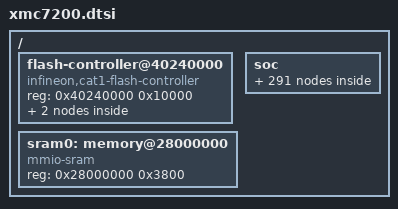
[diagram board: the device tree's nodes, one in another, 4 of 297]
/*
 * Copyright (c) 2023 Cypress Semiconductor Corporation (an Infineon company) or
 * an affiliate of Cypress Semiconductor Corporation
 *
 * SPDX-License-Identifier: Apache-2.0
 */

#include <mem.h>

/ {
	flash-controller@40240000 {
		compatible = "infineon,cat1-flash-controller";
		reg = <0x40240000 0x10000>;
		#address-cells = <1>;
		#size-cells = <1>;

		flash0: flash@10000000 {
			compatible = "soc-nv-flash";
			reg = <0x10000000 0x80000>;
			write-block-size = <512>;
			erase-block-size = <512>;
		};

		flash1: flash@10080000 {
			compatible = "soc-nv-flash";
			reg = <0x10080000 0x200000>;
			write-block-size = <512>;
			erase-block-size = <512>;
		};
	};

	/* 0x0000000028000800  _base_SRAM_CM0P =
	 * ((sram_base_address + sram_start_reserve) + sram_private_for_srom)
	 * TODO: Where better to keep srom private
	 */
	sram0: memory@28000000 {
		compatible = "mmio-sram";
		reg = <0x28000000 0x3800>;
	};

	soc {
		pinctrl: pinctrl@40300000 {
			compatible = "infineon,cat1-pinctrl";
			reg = <0x40300000 0x20000>;
		};

		hsiom: hsiom@40300000 {
			compatible = "infineon,cat1-hsiom";
			reg = <0x40300000 0x4000>;
			system-interrupts = <21 6>, <20 6>;
			status = "disabled";
		};

		gpio_prt0: gpio@40310000 {
			compatible = "infineon,cat1-gpio";
			reg = <0x40310000 0x80>;
			system-interrupts = <22 2>;
			gpio-controller;
			ngpios = <4>;
			status = "disabled";
			#gpio-cells = <2>;
		};

		gpio_prt1: gpio@40310080 {
			compatible = "infineon,cat1-gpio";
			reg = <0x40310080 0x80>;
			system-interrupts = <23 2>;
			gpio-controller;
			ngpios = <7>;
			status = "disabled";
			#gpio-cells = <2>;
		};

		gpio_prt2: gpio@40310100 {
			compatible = "infineon,cat1-gpio";
			reg = <0x40310100 0x80>;
			system-interrupts = <24 2>;
			gpio-controller;
			ngpios = <8>;
			status = "disabled";
			#gpio-cells = <2>;
		};

		gpio_prt3: gpio@40310180 {
			compatible = "infineon,cat1-gpio";
			reg = <0x40310180 0x80>;
			system-interrupts = <25 2>;
			gpio-controller;
			ngpios = <8>;
			status = "disabled";
			#gpio-cells = <2>;
		};

		gpio_prt4: gpio@40310200 {
			compatible = "infineon,cat1-gpio";
			reg = <0x40310200 0x80>;
			system-interrupts = <26 2>;
			gpio-controller;
			ngpios = <7>;
			status = "disabled";
			#gpio-cells = <2>;
		};

		gpio_prt5: gpio@40310280 {
			compatible = "infineon,cat1-gpio";
			reg = <0x40310280 0x80>;
			system-interrupts = <27 2>;
			gpio-controller;
			ngpios = <6>;
			status = "disabled";
			#gpio-cells = <2>;
		};

		gpio_prt6: gpio@40310300 {
			compatible = "infineon,cat1-gpio";
			reg = <0x40310300 0x80>;
			system-interrupts = <28 2>;
			gpio-controller;
			ngpios = <8>;
			status = "disabled";
			#gpio-cells = <2>;
		};

		gpio_prt7: gpio@40310380 {
			compatible = "infineon,cat1-gpio";
			reg = <0x40310380 0x80>;
			system-interrupts = <29 2>;
			gpio-controller;
			ngpios = <8>;
			status = "disabled";
			#gpio-cells = <2>;
		};

		gpio_prt8: gpio@40310400 {
			compatible = "infineon,cat1-gpio";
			reg = <0x40310400 0x80>;
			system-interrupts = <30 2>;
			gpio-controller;
			ngpios = <5>;
			status = "disabled";
			#gpio-cells = <2>;
		};

		gpio_prt9: gpio@40310480 {
			compatible = "infineon,cat1-gpio";
			reg = <0x40310480 0x80>;
			system-interrupts = <31 2>;
			gpio-controller;
			ngpios = <4>;
			status = "disabled";
			#gpio-cells = <2>;
		};

		gpio_prt10: gpio@40310500 {
			compatible = "infineon,cat1-gpio";
			reg = <0x40310500 0x80>;
			system-interrupts = <32 2>;
			gpio-controller;
			ngpios = <8>;
			status = "disabled";
			#gpio-cells = <2>;
		};

		gpio_prt11: gpio@40310580 {
			compatible = "infineon,cat1-gpio";
			reg = <0x40310580 0x80>;
			system-interrupts = <33 2>;
			gpio-controller;
			ngpios = <3>;
			status = "disabled";
			#gpio-cells = <2>;
		};

		gpio_prt12: gpio@40310600 {
			compatible = "infineon,cat1-gpio";
			reg = <0x40310600 0x80>;
			system-interrupts = <34 2>;
			gpio-controller;
			ngpios = <8>;
			status = "disabled";
			#gpio-cells = <2>;
		};

		gpio_prt13: gpio@40310680 {
			compatible = "infineon,cat1-gpio";
			reg = <0x40310680 0x80>;
			system-interrupts = <35 2>;
			gpio-controller;
			ngpios = <8>;
			status = "disabled";
			#gpio-cells = <2>;
		};

		gpio_prt14: gpio@40310700 {
			compatible = "infineon,cat1-gpio";
			reg = <0x40310700 0x80>;
			system-interrupts = <36 2>;
			gpio-controller;
			ngpios = <8>;
			status = "disabled";
			#gpio-cells = <2>;
		};

		gpio_prt15: gpio@40310780 {
			compatible = "infineon,cat1-gpio";
			reg = <0x40310780 0x80>;
			system-interrupts = <37 2>;
			gpio-controller;
			ngpios = <4>;
			status = "disabled";
			#gpio-cells = <2>;
		};

		gpio_prt16: gpio@40310800 {
			compatible = "infineon,cat1-gpio";
			reg = <0x40310800 0x80>;
			system-interrupts = <38 2>;
			gpio-controller;
			ngpios = <8>;
			status = "disabled";
			#gpio-cells = <2>;
		};

		gpio_prt17: gpio@40310880 {
			compatible = "infineon,cat1-gpio";
			reg = <0x40310880 0x80>;
			system-interrupts = <39 2>;
			gpio-controller;
			ngpios = <8>;
			status = "disabled";
			#gpio-cells = <2>;
		};

		gpio_prt18: gpio@40310900 {
			compatible = "infineon,cat1-gpio";
			reg = <0x40310900 0x80>;
			system-interrupts = <40 2>;
			gpio-controller;
			ngpios = <8>;
			status = "disabled";
			#gpio-cells = <2>;
		};

		gpio_prt19: gpio@40310980 {
			compatible = "infineon,cat1-gpio";
			reg = <0x40310980 0x80>;
			system-interrupts = <41 2>;
			gpio-controller;
			ngpios = <5>;
			status = "disabled";
			#gpio-cells = <2>;
		};

		gpio_prt20: gpio@40310a00 {
			compatible = "infineon,cat1-gpio";
			reg = <0x40310a00 0x80>;
			system-interrupts = <42 2>;
			gpio-controller;
			ngpios = <8>;
			status = "disabled";
			#gpio-cells = <2>;
		};

		gpio_prt21: gpio@40310a80 {
			compatible = "infineon,cat1-gpio";
			reg = <0x40310a80 0x80>;
			system-interrupts = <43 2>;
			gpio-controller;
			ngpios = <8>;
			status = "disabled";
			#gpio-cells = <2>;
		};

		gpio_prt22: gpio@40310b00 {
			compatible = "infineon,cat1-gpio";
			reg = <0x40310b00 0x80>;
			system-interrupts = <44 2>;
			gpio-controller;
			ngpios = <8>;
			status = "disabled";
			#gpio-cells = <2>;
		};

		gpio_prt23: gpio@40310b80 {
			compatible = "infineon,cat1-gpio";
			reg = <0x40310b80 0x80>;
			system-interrupts = <45 2>;
			gpio-controller;
			ngpios = <8>;
			status = "disabled";
			#gpio-cells = <2>;
		};

		gpio_prt24: gpio@40310c00 {
			compatible = "infineon,cat1-gpio";
			reg = <0x40310c00 0x80>;
			system-interrupts = <52 2>;
			gpio-controller;
			ngpios = <5>;
			status = "disabled";
			#gpio-cells = <2>;
		};

		gpio_prt25: gpio@40310c80 {
			compatible = "infineon,cat1-gpio";
			reg = <0x40310c80 0x80>;
			system-interrupts = <53 2>;
			gpio-controller;
			ngpios = <8>;
			status = "disabled";
			#gpio-cells = <2>;
		};

		gpio_prt26: gpio@40310d00 {
			compatible = "infineon,cat1-gpio";
			reg = <0x40310d00 0x80>;
			system-interrupts = <54 2>;
			gpio-controller;
			ngpios = <8>;
			status = "disabled";
			#gpio-cells = <2>;
		};

		gpio_prt27: gpio@40310d80 {
			compatible = "infineon,cat1-gpio";
			reg = <0x40310d80 0x80>;
			system-interrupts = <55 2>;
			gpio-controller;
			ngpios = <8>;
			status = "disabled";
			#gpio-cells = <2>;
		};

		gpio_prt28: gpio@40310e00 {
			compatible = "infineon,cat1-gpio";
			reg = <0x40310e00 0x80>;
			system-interrupts = <46 2>;
			gpio-controller;
			ngpios = <8>;
			status = "disabled";
			#gpio-cells = <2>;
		};

		gpio_prt29: gpio@40310e80 {
			compatible = "infineon,cat1-gpio";
			reg = <0x40310e80 0x80>;
			system-interrupts = <47 2>;
			gpio-controller;
			ngpios = <8>;
			status = "disabled";
			#gpio-cells = <2>;
		};

		gpio_prt30: gpio@40310f00 {
			compatible = "infineon,cat1-gpio";
			reg = <0x40310f00 0x80>;
			system-interrupts = <48 2>;
			gpio-controller;
			ngpios = <4>;
			status = "disabled";
			#gpio-cells = <2>;
		};

		gpio_prt31: gpio@40310f80 {
			compatible = "infineon,cat1-gpio";
			reg = <0x40310f80 0x80>;
			system-interrupts = <49 2>;
			gpio-controller;
			ngpios = <3>;
			status = "disabled";
			#gpio-cells = <2>;
		};

		gpio_prt32: gpio@40311000 {
			compatible = "infineon,cat1-gpio";
			reg = <0x40311000 0x80>;
			system-interrupts = <50 2>;
			gpio-controller;
			ngpios = <8>;
			status = "disabled";
			#gpio-cells = <2>;
		};

		gpio_prt33: gpio@40311080 {
			compatible = "infineon,cat1-gpio";
			reg = <0x40311080 0x80>;
			system-interrupts = <56 2>;
			gpio-controller;
			ngpios = <8>;
			status = "disabled";
			#gpio-cells = <2>;
		};

		gpio_prt34: gpio@40311100 {
			compatible = "infineon,cat1-gpio";
			reg = <0x40311100 0x80>;
			system-interrupts = <57 2>;
			gpio-controller;
			ngpios = <8>;
			status = "disabled";
			#gpio-cells = <2>;
		};

		scb0: scb@40600000 {
			compatible = "infineon,cat1-scb";
			reg = <0x40600000 0xfd0>;
			system-interrupts = <18 6>;
			status = "disabled";
		};

		scb1: scb@40610000 {
			compatible = "infineon,cat1-scb";
			reg = <0x40610000 0xfd0>;
			system-interrupts = <113 6>;
			status = "disabled";
		};

		scb2: scb@40620000 {
			compatible = "infineon,cat1-scb";
			reg = <0x40620000 0xfd0>;
			system-interrupts = <114 6>;
			status = "disabled";
		};

		scb3: scb@40630000 {
			compatible = "infineon,cat1-scb";
			reg = <0x40630000 0xfd0>;
			system-interrupts = <115 6>;
			status = "disabled";
		};

		scb4: scb@40640000 {
			compatible = "infineon,cat1-scb";
			reg = <0x40640000 0xfd0>;
			system-interrupts = <116 6>;
			status = "disabled";
		};

		scb5: scb@40650000 {
			compatible = "infineon,cat1-scb";
			reg = <0x40650000 0xfd0>;
			system-interrupts = <117 6>;
			status = "disabled";
		};

		scb6: scb@40660000 {
			compatible = "infineon,cat1-scb";
			reg = <0x40660000 0xfd0>;
			system-interrupts = <118 6>;
			status = "disabled";
		};

		scb7: scb@40670000 {
			compatible = "infineon,cat1-scb";
			reg = <0x40670000 0xfd0>;
			system-interrupts = <119 6>;
			status = "disabled";
		};

		scb8: scb@40680000 {
			compatible = "infineon,cat1-scb";
			reg = <0x40680000 0xfd0>;
			system-interrupts = <120 6>;
			status = "disabled";
		};

		scb9: scb@40690000 {
			compatible = "infineon,cat1-scb";
			reg = <0x40690000 0xfd0>;
			system-interrupts = <121 6>;
			status = "disabled";
		};

		scb10: scb@406a0000 {
			compatible = "infineon,cat1-scb";
			reg = <0x406a0000 0xfd0>;
			system-interrupts = <122 6>;
			status = "disabled";
		};

		watchdog0: watchdog@4026c000 {
			compatible = "infineon,cat1-watchdog";
			reg = <0x4026c000 0x80>;
			system-interrupts = <16 6>;
			status = "disabled";
		};

		mcwdt0: mcwdt@40268000 {
			compatible = "infineon,cat1-lp-timer";
			reg = <0x40268000 0x100>;
			system-interrupts = <13 6>;
			status = "disabled";
		};

		mcwdt1: mcwdt@40268100 {
			compatible = "infineon,cat1-lp-timer";
			reg = <0x40268100 0x100>;
			system-interrupts = <14 6>;
			status = "disabled";
		};

		mcwdt2: mcwdt@40268200 {
			compatible = "infineon,cat1-lp-timer";
			reg = <0x40268200 0x100>;
			system-interrupts = <15 6>;
			status = "disabled";
		};

		counter0_0_0: counter@40380000 {
			compatible = "infineon,cat1-counter";
			reg = <0x40380000 0x80>;
			system-interrupts = <519 6>;
			resolution = <16>;
			status = "disabled";
		};

		counter0_0_1: counter@40380080 {
			compatible = "infineon,cat1-counter";
			reg = <0x40380080 0x80>;
			system-interrupts = <520 6>;
			resolution = <16>;
			status = "disabled";
		};

		counter0_0_2: counter@40380100 {
			compatible = "infineon,cat1-counter";
			reg = <0x40380100 0x80>;
			system-interrupts = <521 6>;
			resolution = <16>;
			status = "disabled";
		};

		counter0_1_0: counter@40388000 {
			compatible = "infineon,cat1-counter";
			reg = <0x40388000 0x80>;
			system-interrupts = <534 6>;
			resolution = <16>;
			status = "disabled";
		};

		counter0_1_1: counter@40388080 {
			compatible = "infineon,cat1-counter";
			reg = <0x40388080 0x80>;
			system-interrupts = <535 6>;
			resolution = <16>;
			status = "disabled";
		};

		counter0_1_2: counter@40388100 {
			compatible = "infineon,cat1-counter";
			reg = <0x40388100 0x80>;
			system-interrupts = <536 6>;
			resolution = <16>;
			status = "disabled";
		};

		counter0_2_0: counter@40390000 {
			compatible = "infineon,cat1-counter";
			reg = <0x40390000 0x80>;
			system-interrupts = <550 6>;
			resolution = <32>;
			status = "disabled";
		};

		counter0_2_1: counter@40390080 {
			compatible = "infineon,cat1-counter";
			reg = <0x40390080 0x80>;
			system-interrupts = <551 6>;
			resolution = <32>;
			status = "disabled";
		};

		counter0_2_2: counter@40390100 {
			compatible = "infineon,cat1-counter";
			reg = <0x40390100 0x80>;
			system-interrupts = <552 6>;
			resolution = <32>;
			status = "disabled";
		};

		counter1_0_0: counter@40580000 {
			compatible = "infineon,cat1-counter";
			reg = <0x40580000 0x80>;
			system-interrupts = <435 6>;
			resolution = <16>;
			status = "disabled";
		};

		counter1_0_1: counter@40580080 {
			compatible = "infineon,cat1-counter";
			reg = <0x40580080 0x80>;
			system-interrupts = <436 6>;
			resolution = <16>;
			status = "disabled";
		};

		counter1_0_2: counter@40580100 {
			compatible = "infineon,cat1-counter";
			reg = <0x40580100 0x80>;
			system-interrupts = <437 6>;
			resolution = <16>;
			status = "disabled";
		};

		counter1_0_3: counter@40580180 {
			compatible = "infineon,cat1-counter";
			reg = <0x40580180 0x80>;
			system-interrupts = <438 6>;
			resolution = <16>;
			status = "disabled";
		};

		counter1_0_4: counter@40580200 {
			compatible = "infineon,cat1-counter";
			reg = <0x40580200 0x80>;
			system-interrupts = <439 6>;
			resolution = <16>;
			status = "disabled";
		};

		counter1_0_5: counter@40580280 {
			compatible = "infineon,cat1-counter";
			reg = <0x40580280 0x80>;
			system-interrupts = <440 6>;
			resolution = <16>;
			status = "disabled";
		};

		counter1_0_6: counter@40580300 {
			compatible = "infineon,cat1-counter";
			reg = <0x40580300 0x80>;
			system-interrupts = <441 6>;
			resolution = <16>;
			status = "disabled";
		};

		counter1_0_7: counter@40580380 {
			compatible = "infineon,cat1-counter";
			reg = <0x40580380 0x80>;
			system-interrupts = <442 6>;
			resolution = <16>;
			status = "disabled";
		};

		counter1_0_8: counter@40580400 {
			compatible = "infineon,cat1-counter";
			reg = <0x40580400 0x80>;
			system-interrupts = <443 6>;
			resolution = <16>;
			status = "disabled";
		};

		counter1_0_9: counter@40580480 {
			compatible = "infineon,cat1-counter";
			reg = <0x40580480 0x80>;
			system-interrupts = <444 6>;
			resolution = <16>;
			status = "disabled";
		};

		counter1_0_10: counter@40580500 {
			compatible = "infineon,cat1-counter";
			reg = <0x40580500 0x80>;
			system-interrupts = <445 6>;
			resolution = <16>;
			status = "disabled";
		};

		counter1_0_11: counter@40580580 {
			compatible = "infineon,cat1-counter";
			reg = <0x40580580 0x80>;
			system-interrupts = <446 6>;
			resolution = <16>;
			status = "disabled";
		};

		counter1_0_12: counter@40580600 {
			compatible = "infineon,cat1-counter";
			reg = <0x40580600 0x80>;
			system-interrupts = <447 6>;
			resolution = <16>;
			status = "disabled";
		};

		counter1_0_13: counter@40580680 {
			compatible = "infineon,cat1-counter";
			reg = <0x40580680 0x80>;
			system-interrupts = <448 6>;
			resolution = <16>;
			status = "disabled";
		};

		counter1_0_14: counter@40580700 {
			compatible = "infineon,cat1-counter";
			reg = <0x40580700 0x80>;
			system-interrupts = <449 6>;
			resolution = <16>;
			status = "disabled";
		};

		counter1_0_15: counter@40580780 {
			compatible = "infineon,cat1-counter";
			reg = <0x40580780 0x80>;
			system-interrupts = <450 6>;
			resolution = <16>;
			status = "disabled";
		};

		counter1_0_16: counter@40580800 {
			compatible = "infineon,cat1-counter";
			reg = <0x40580800 0x80>;
			system-interrupts = <451 6>;
			resolution = <16>;
			status = "disabled";
		};

		counter1_0_17: counter@40580880 {
			compatible = "infineon,cat1-counter";
			reg = <0x40580880 0x80>;
			system-interrupts = <452 6>;
			resolution = <16>;
			status = "disabled";
		};

		counter1_0_18: counter@40580900 {
			compatible = "infineon,cat1-counter";
			reg = <0x40580900 0x80>;
			system-interrupts = <453 6>;
			resolution = <16>;
			status = "disabled";
		};

		counter1_0_19: counter@40580980 {
			compatible = "infineon,cat1-counter";
			reg = <0x40580980 0x80>;
			system-interrupts = <454 6>;
			resolution = <16>;
			status = "disabled";
		};

		counter1_0_20: counter@40580a00 {
			compatible = "infineon,cat1-counter";
			reg = <0x40580a00 0x80>;
			system-interrupts = <455 6>;
			resolution = <16>;
			status = "disabled";
		};

		counter1_0_21: counter@40580a80 {
			compatible = "infineon,cat1-counter";
			reg = <0x40580a80 0x80>;
			system-interrupts = <456 6>;
			resolution = <16>;
			status = "disabled";
		};

		counter1_0_22: counter@40580b00 {
			compatible = "infineon,cat1-counter";
			reg = <0x40580b00 0x80>;
			system-interrupts = <457 6>;
			resolution = <16>;
			status = "disabled";
		};

		counter1_0_23: counter@40580b80 {
			compatible = "infineon,cat1-counter";
			reg = <0x40580b80 0x80>;
			system-interrupts = <458 6>;
			resolution = <16>;
			status = "disabled";
		};

		counter1_0_24: counter@40580c00 {
			compatible = "infineon,cat1-counter";
			reg = <0x40580c00 0x80>;
			system-interrupts = <459 6>;
			resolution = <16>;
			status = "disabled";
		};

		counter1_0_25: counter@40580c80 {
			compatible = "infineon,cat1-counter";
			reg = <0x40580c80 0x80>;
			system-interrupts = <460 6>;
			resolution = <16>;
			status = "disabled";
		};

		counter1_0_26: counter@40580d00 {
			compatible = "infineon,cat1-counter";
			reg = <0x40580d00 0x80>;
			system-interrupts = <461 6>;
			resolution = <16>;
			status = "disabled";
		};

		counter1_0_27: counter@40580d80 {
			compatible = "infineon,cat1-counter";
			reg = <0x40580d80 0x80>;
			system-interrupts = <462 6>;
			resolution = <16>;
			status = "disabled";
		};

		counter1_0_28: counter@40580e00 {
			compatible = "infineon,cat1-counter";
			reg = <0x40580e00 0x80>;
			system-interrupts = <463 6>;
			resolution = <16>;
			status = "disabled";
		};

		counter1_0_29: counter@40580e80 {
			compatible = "infineon,cat1-counter";
			reg = <0x40580e80 0x80>;
			system-interrupts = <464 6>;
			resolution = <16>;
			status = "disabled";
		};

		counter1_0_30: counter@40580f00 {
			compatible = "infineon,cat1-counter";
			reg = <0x40580f00 0x80>;
			system-interrupts = <465 6>;
			resolution = <16>;
			status = "disabled";
		};

		counter1_0_31: counter@40580f80 {
			compatible = "infineon,cat1-counter";
			reg = <0x40580f80 0x80>;
			system-interrupts = <466 6>;
			resolution = <16>;
			status = "disabled";
		};

		counter1_0_32: counter@40581000 {
			compatible = "infineon,cat1-counter";
			reg = <0x40581000 0x80>;
			system-interrupts = <467 6>;
			resolution = <16>;
			status = "disabled";
		};

		counter1_0_33: counter@40581080 {
			compatible = "infineon,cat1-counter";
			reg = <0x40581080 0x80>;
			system-interrupts = <468 6>;
			resolution = <16>;
			status = "disabled";
		};

		counter1_0_34: counter@40581100 {
			compatible = "infineon,cat1-counter";
			reg = <0x40581100 0x80>;
			system-interrupts = <469 6>;
			resolution = <16>;
			status = "disabled";
		};

		counter1_0_35: counter@40581180 {
			compatible = "infineon,cat1-counter";
			reg = <0x40581180 0x80>;
			system-interrupts = <470 6>;
			resolution = <16>;
			status = "disabled";
		};

		counter1_0_36: counter@40581200 {
			compatible = "infineon,cat1-counter";
			reg = <0x40581200 0x80>;
			system-interrupts = <471 6>;
			resolution = <16>;
			status = "disabled";
		};

		counter1_0_37: counter@40581280 {
			compatible = "infineon,cat1-counter";
			reg = <0x40581280 0x80>;
			system-interrupts = <472 6>;
			resolution = <16>;
			status = "disabled";
		};

		counter1_0_38: counter@40581300 {
			compatible = "infineon,cat1-counter";
			reg = <0x40581300 0x80>;
			system-interrupts = <473 6>;
			resolution = <16>;
			status = "disabled";
		};

		counter1_0_39: counter@40581380 {
			compatible = "infineon,cat1-counter";
			reg = <0x40581380 0x80>;
			system-interrupts = <474 6>;
			resolution = <16>;
			status = "disabled";
		};

		counter1_0_40: counter@40581400 {
			compatible = "infineon,cat1-counter";
			reg = <0x40581400 0x80>;
			system-interrupts = <475 6>;
			resolution = <16>;
			status = "disabled";
		};

		counter1_0_41: counter@40581480 {
			compatible = "infineon,cat1-counter";
			reg = <0x40581480 0x80>;
			system-interrupts = <476 6>;
			resolution = <16>;
			status = "disabled";
		};

		counter1_0_42: counter@40581500 {
			compatible = "infineon,cat1-counter";
			reg = <0x40581500 0x80>;
			system-interrupts = <477 6>;
			resolution = <16>;
			status = "disabled";
		};

		counter1_0_43: counter@40581580 {
			compatible = "infineon,cat1-counter";
			reg = <0x40581580 0x80>;
			system-interrupts = <478 6>;
			resolution = <16>;
			status = "disabled";
		};

		counter1_0_44: counter@40581600 {
			compatible = "infineon,cat1-counter";
			reg = <0x40581600 0x80>;
			system-interrupts = <479 6>;
			resolution = <16>;
			status = "disabled";
		};

		counter1_0_45: counter@40581680 {
			compatible = "infineon,cat1-counter";
			reg = <0x40581680 0x80>;
			system-interrupts = <480 6>;
			resolution = <16>;
			status = "disabled";
		};

		counter1_0_46: counter@40581700 {
			compatible = "infineon,cat1-counter";
			reg = <0x40581700 0x80>;
			system-interrupts = <481 6>;
			resolution = <16>;
			status = "disabled";
		};

		counter1_0_47: counter@40581780 {
			compatible = "infineon,cat1-counter";
			reg = <0x40581780 0x80>;
			system-interrupts = <482 6>;
			resolution = <16>;
			status = "disabled";
		};

		counter1_0_48: counter@40581800 {
			compatible = "infineon,cat1-counter";
			reg = <0x40581800 0x80>;
			system-interrupts = <483 6>;
			resolution = <16>;
			status = "disabled";
		};

		counter1_0_49: counter@40581880 {
			compatible = "infineon,cat1-counter";
			reg = <0x40581880 0x80>;
			system-interrupts = <484 6>;
			resolution = <16>;
			status = "disabled";
		};

		counter1_0_50: counter@40581900 {
			compatible = "infineon,cat1-counter";
			reg = <0x40581900 0x80>;
			system-interrupts = <485 6>;
			resolution = <16>;
			status = "disabled";
		};

		counter1_0_51: counter@40581980 {
			compatible = "infineon,cat1-counter";
			reg = <0x40581980 0x80>;
			system-interrupts = <486 6>;
			resolution = <16>;
			status = "disabled";
		};

		counter1_0_52: counter@40581a00 {
			compatible = "infineon,cat1-counter";
			reg = <0x40581a00 0x80>;
			system-interrupts = <487 6>;
			resolution = <16>;
			status = "disabled";
		};

		counter1_0_53: counter@40581a80 {
			compatible = "infineon,cat1-counter";
			reg = <0x40581a80 0x80>;
			system-interrupts = <488 6>;
			resolution = <16>;
			status = "disabled";
		};

		counter1_0_54: counter@40581b00 {
			compatible = "infineon,cat1-counter";
			reg = <0x40581b00 0x80>;
			system-interrupts = <489 6>;
			resolution = <16>;
			status = "disabled";
		};

		counter1_0_55: counter@40581b80 {
			compatible = "infineon,cat1-counter";
			reg = <0x40581b80 0x80>;
			system-interrupts = <490 6>;
			resolution = <16>;
			status = "disabled";
		};

		counter1_0_56: counter@40581c00 {
			compatible = "infineon,cat1-counter";
			reg = <0x40581c00 0x80>;
			system-interrupts = <491 6>;
			resolution = <16>;
			status = "disabled";
		};

		counter1_0_57: counter@40581c80 {
			compatible = "infineon,cat1-counter";
			reg = <0x40581c80 0x80>;
			system-interrupts = <492 6>;
			resolution = <16>;
			status = "disabled";
		};

		counter1_0_58: counter@40581d00 {
			compatible = "infineon,cat1-counter";
			reg = <0x40581d00 0x80>;
			system-interrupts = <493 6>;
			resolution = <16>;
			status = "disabled";
		};

		counter1_0_59: counter@40581d80 {
			compatible = "infineon,cat1-counter";
			reg = <0x40581d80 0x80>;
			system-interrupts = <494 6>;
			resolution = <16>;
			status = "disabled";
		};

		counter1_0_60: counter@40581e00 {
			compatible = "infineon,cat1-counter";
			reg = <0x40581e00 0x80>;
			system-interrupts = <495 6>;
			resolution = <16>;
			status = "disabled";
		};

		counter1_0_61: counter@40581e80 {
			compatible = "infineon,cat1-counter";
			reg = <0x40581e80 0x80>;
			system-interrupts = <496 6>;
			resolution = <16>;
			status = "disabled";
		};

		counter1_0_62: counter@40581f00 {
			compatible = "infineon,cat1-counter";
			reg = <0x40581f00 0x80>;
			system-interrupts = <497 6>;
			resolution = <16>;
			status = "disabled";
		};

		counter1_0_63: counter@40581f80 {
			compatible = "infineon,cat1-counter";
			reg = <0x40581f80 0x80>;
			system-interrupts = <498 6>;
			resolution = <16>;
			status = "disabled";
		};

		counter1_0_64: counter@40582000 {
			compatible = "infineon,cat1-counter";
			reg = <0x40582000 0x80>;
			system-interrupts = <499 6>;
			resolution = <16>;
			status = "disabled";
		};

		counter1_0_65: counter@40582080 {
			compatible = "infineon,cat1-counter";
			reg = <0x40582080 0x80>;
			system-interrupts = <500 6>;
			resolution = <16>;
			status = "disabled";
		};

		counter1_0_66: counter@40582100 {
			compatible = "infineon,cat1-counter";
			reg = <0x40582100 0x80>;
			system-interrupts = <501 6>;
			resolution = <16>;
			status = "disabled";
		};

		counter1_0_67: counter@40582180 {
			compatible = "infineon,cat1-counter";
			reg = <0x40582180 0x80>;
			system-interrupts = <502 6>;
			resolution = <16>;
			status = "disabled";
		};

		counter1_0_68: counter@40582200 {
			compatible = "infineon,cat1-counter";
			reg = <0x40582200 0x80>;
			system-interrupts = <503 6>;
			resolution = <16>;
			status = "disabled";
		};

		counter1_0_69: counter@40582280 {
			compatible = "infineon,cat1-counter";
			reg = <0x40582280 0x80>;
			system-interrupts = <504 6>;
			resolution = <16>;
			status = "disabled";
		};

		counter1_0_70: counter@40582300 {
			compatible = "infineon,cat1-counter";
			reg = <0x40582300 0x80>;
			system-interrupts = <505 6>;
			resolution = <16>;
			status = "disabled";
		};

		counter1_0_71: counter@40582380 {
			compatible = "infineon,cat1-counter";
			reg = <0x40582380 0x80>;
			system-interrupts = <506 6>;
			resolution = <16>;
			status = "disabled";
		};

		counter1_0_72: counter@40582400 {
			compatible = "infineon,cat1-counter";
			reg = <0x40582400 0x80>;
			system-interrupts = <507 6>;
			resolution = <16>;
			status = "disabled";
		};

		counter1_0_73: counter@40582480 {
			compatible = "infineon,cat1-counter";
			reg = <0x40582480 0x80>;
			system-interrupts = <508 6>;
			resolution = <16>;
			status = "disabled";
		};

		counter1_0_74: counter@40582500 {
			compatible = "infineon,cat1-counter";
			reg = <0x40582500 0x80>;
			system-interrupts = <509 6>;
			resolution = <16>;
			status = "disabled";
		};

		counter1_0_75: counter@40582580 {
			compatible = "infineon,cat1-counter";
			reg = <0x40582580 0x80>;
			system-interrupts = <510 6>;
			resolution = <16>;
			status = "disabled";
		};

		counter1_0_76: counter@40582600 {
			compatible = "infineon,cat1-counter";
			reg = <0x40582600 0x80>;
			system-interrupts = <511 6>;
			resolution = <16>;
			status = "disabled";
		};

		counter1_0_77: counter@40582680 {
			compatible = "infineon,cat1-counter";
			reg = <0x40582680 0x80>;
			system-interrupts = <512 6>;
			resolution = <16>;
			status = "disabled";
		};

		counter1_0_78: counter@40582700 {
			compatible = "infineon,cat1-counter";
			reg = <0x40582700 0x80>;
			system-interrupts = <513 6>;
			resolution = <16>;
			status = "disabled";
		};

		counter1_0_79: counter@40582780 {
			compatible = "infineon,cat1-counter";
			reg = <0x40582780 0x80>;
			system-interrupts = <514 6>;
			resolution = <16>;
			status = "disabled";
		};

		counter1_0_80: counter@40582800 {
			compatible = "infineon,cat1-counter";
			reg = <0x40582800 0x80>;
			system-interrupts = <515 6>;
			resolution = <16>;
			status = "disabled";
		};

		counter1_0_81: counter@40582880 {
			compatible = "infineon,cat1-counter";
			reg = <0x40582880 0x80>;
			system-interrupts = <516 6>;
			resolution = <16>;
			status = "disabled";
		};

		counter1_0_82: counter@40582900 {
			compatible = "infineon,cat1-counter";
			reg = <0x40582900 0x80>;
			system-interrupts = <517 6>;
			resolution = <16>;
			status = "disabled";
		};

		counter1_0_83: counter@40582980 {
			compatible = "infineon,cat1-counter";
			reg = <0x40582980 0x80>;
			system-interrupts = <518 6>;
			resolution = <16>;
			status = "disabled";
		};

		counter1_1_0: counter@40588000 {
			compatible = "infineon,cat1-counter";
			reg = <0x40588000 0x80>;
			system-interrupts = <522 6>;
			resolution = <16>;
			status = "disabled";
		};

		counter1_1_1: counter@40588080 {
			compatible = "infineon,cat1-counter";
			reg = <0x40588080 0x80>;
			system-interrupts = <523 6>;
			resolution = <16>;
			status = "disabled";
		};

		counter1_1_2: counter@40588100 {
			compatible = "infineon,cat1-counter";
			reg = <0x40588100 0x80>;
			system-interrupts = <524 6>;
			resolution = <16>;
			status = "disabled";
		};

		counter1_1_3: counter@40588180 {
			compatible = "infineon,cat1-counter";
			reg = <0x40588180 0x80>;
			system-interrupts = <525 6>;
			resolution = <16>;
			status = "disabled";
		};

		counter1_1_4: counter@40588200 {
			compatible = "infineon,cat1-counter";
			reg = <0x40588200 0x80>;
			system-interrupts = <526 6>;
			resolution = <16>;
			status = "disabled";
		};

		counter1_1_5: counter@40588280 {
			compatible = "infineon,cat1-counter";
			reg = <0x40588280 0x80>;
			system-interrupts = <527 6>;
			resolution = <16>;
			status = "disabled";
		};

		counter1_1_6: counter@40588300 {
			compatible = "infineon,cat1-counter";
			reg = <0x40588300 0x80>;
			system-interrupts = <528 6>;
			resolution = <16>;
			status = "disabled";
		};

		counter1_1_7: counter@40588380 {
			compatible = "infineon,cat1-counter";
			reg = <0x40588380 0x80>;
			system-interrupts = <529 6>;
			resolution = <16>;
			status = "disabled";
		};

		counter1_1_8: counter@40588400 {
			compatible = "infineon,cat1-counter";
			reg = <0x40588400 0x80>;
			system-interrupts = <530 6>;
			resolution = <16>;
			status = "disabled";
		};

		counter1_1_9: counter@40588480 {
			compatible = "infineon,cat1-counter";
			reg = <0x40588480 0x80>;
			system-interrupts = <531 6>;
			resolution = <16>;
			status = "disabled";
		};

		counter1_1_10: counter@40588500 {
			compatible = "infineon,cat1-counter";
			reg = <0x40588500 0x80>;
			system-interrupts = <532 6>;
			resolution = <16>;
			status = "disabled";
		};

		counter1_1_11: counter@40588580 {
			compatible = "infineon,cat1-counter";
			reg = <0x40588580 0x80>;
			system-interrupts = <533 6>;
			resolution = <16>;
			status = "disabled";
		};

		counter1_2_0: counter@40590000 {
			compatible = "infineon,cat1-counter";
			reg = <0x40590000 0x80>;
			system-interrupts = <537 6>;
			resolution = <32>;
			status = "disabled";
		};

		counter1_2_1: counter@40590080 {
			compatible = "infineon,cat1-counter";
			reg = <0x40590080 0x80>;
			system-interrupts = <538 6>;
			resolution = <32>;
			status = "disabled";
		};

		counter1_2_2: counter@40590100 {
			compatible = "infineon,cat1-counter";
			reg = <0x40590100 0x80>;
			system-interrupts = <539 6>;
			resolution = <32>;
			status = "disabled";
		};

		counter1_2_3: counter@40590180 {
			compatible = "infineon,cat1-counter";
			reg = <0x40590180 0x80>;
			system-interrupts = <540 6>;
			resolution = <32>;
			status = "disabled";
		};

		counter1_2_4: counter@40590200 {
			compatible = "infineon,cat1-counter";
			reg = <0x40590200 0x80>;
			system-interrupts = <541 6>;
			resolution = <32>;
			status = "disabled";
		};

		counter1_2_5: counter@40590280 {
			compatible = "infineon,cat1-counter";
			reg = <0x40590280 0x80>;
			system-interrupts = <542 6>;
			resolution = <32>;
			status = "disabled";
		};

		counter1_2_6: counter@40590300 {
			compatible = "infineon,cat1-counter";
			reg = <0x40590300 0x80>;
			system-interrupts = <543 6>;
			resolution = <32>;
			status = "disabled";
		};

		counter1_2_7: counter@40590380 {
			compatible = "infineon,cat1-counter";
			reg = <0x40590380 0x80>;
			system-interrupts = <544 6>;
			resolution = <32>;
			status = "disabled";
		};

		counter1_2_8: counter@40590400 {
			compatible = "infineon,cat1-counter";
			reg = <0x40590400 0x80>;
			system-interrupts = <545 6>;
			resolution = <32>;
			status = "disabled";
		};

		counter1_2_9: counter@40590480 {
			compatible = "infineon,cat1-counter";
			reg = <0x40590480 0x80>;
			system-interrupts = <546 6>;
			resolution = <32>;
			status = "disabled";
		};

		counter1_2_10: counter@40590500 {
			compatible = "infineon,cat1-counter";
			reg = <0x40590500 0x80>;
			system-interrupts = <547 6>;
			resolution = <32>;
			status = "disabled";
		};

		counter1_2_11: counter@40590580 {
			compatible = "infineon,cat1-counter";
			reg = <0x40590580 0x80>;
			system-interrupts = <548 6>;
			resolution = <32>;
			status = "disabled";
		};

		counter1_2_12: counter@40590600 {
			compatible = "infineon,cat1-counter";
			reg = <0x40590600 0x80>;
			system-interrupts = <549 6>;
			resolution = <32>;
			status = "disabled";
		};

		pwm0_0_0: pwm@40380000 {
			compatible = "infineon,cat1-pwm";
			reg = <0x40380000 0x80>;
			system-interrupts = <519 6>;
			resolution = <16>;
			status = "disabled";
		};

		pwm0_0_1: pwm@40380080 {
			compatible = "infineon,cat1-pwm";
			reg = <0x40380080 0x80>;
			system-interrupts = <520 6>;
			resolution = <16>;
			status = "disabled";
		};

		pwm0_0_2: pwm@40380100 {
			compatible = "infineon,cat1-pwm";
			reg = <0x40380100 0x80>;
			system-interrupts = <521 6>;
			resolution = <16>;
			status = "disabled";
		};

		pwm0_1_0: pwm@40388000 {
			compatible = "infineon,cat1-pwm";
			reg = <0x40388000 0x80>;
			system-interrupts = <534 6>;
			resolution = <16>;
			status = "disabled";
		};

		pwm0_1_1: pwm@40388080 {
			compatible = "infineon,cat1-pwm";
			reg = <0x40388080 0x80>;
			system-interrupts = <535 6>;
			resolution = <16>;
			status = "disabled";
		};

		pwm0_1_2: pwm@40388100 {
			compatible = "infineon,cat1-pwm";
			reg = <0x40388100 0x80>;
			system-interrupts = <536 6>;
			resolution = <16>;
			status = "disabled";
		};

		pwm0_2_0: pwm@40390000 {
			compatible = "infineon,cat1-pwm";
			reg = <0x40390000 0x80>;
			system-interrupts = <550 6>;
			resolution = <32>;
			status = "disabled";
		};

		pwm0_2_1: pwm@40390080 {
			compatible = "infineon,cat1-pwm";
			reg = <0x40390080 0x80>;
			system-interrupts = <551 6>;
			resolution = <32>;
			status = "disabled";
		};

		pwm0_2_2: pwm@40390100 {
			compatible = "infineon,cat1-pwm";
			reg = <0x40390100 0x80>;
			system-interrupts = <552 6>;
			resolution = <32>;
			status = "disabled";
		};

		pwm1_0_0: pwm@40580000 {
			compatible = "infineon,cat1-pwm";
			reg = <0x40580000 0x80>;
			system-interrupts = <435 6>;
			resolution = <16>;
			status = "disabled";
		};

		pwm1_0_1: pwm@40580080 {
			compatible = "infineon,cat1-pwm";
			reg = <0x40580080 0x80>;
			system-interrupts = <436 6>;
			resolution = <16>;
			status = "disabled";
		};

		pwm1_0_2: pwm@40580100 {
			compatible = "infineon,cat1-pwm";
			reg = <0x40580100 0x80>;
			system-interrupts = <437 6>;
			resolution = <16>;
			status = "disabled";
		};

		pwm1_0_3: pwm@40580180 {
			compatible = "infineon,cat1-pwm";
			reg = <0x40580180 0x80>;
			system-interrupts = <438 6>;
			resolution = <16>;
			status = "disabled";
		};

		pwm1_0_4: pwm@40580200 {
			compatible = "infineon,cat1-pwm";
			reg = <0x40580200 0x80>;
			system-interrupts = <439 6>;
			resolution = <16>;
			status = "disabled";
		};

		pwm1_0_5: pwm@40580280 {
			compatible = "infineon,cat1-pwm";
			reg = <0x40580280 0x80>;
			system-interrupts = <440 6>;
			resolution = <16>;
			status = "disabled";
		};

		pwm1_0_6: pwm@40580300 {
			compatible = "infineon,cat1-pwm";
			reg = <0x40580300 0x80>;
			system-interrupts = <441 6>;
			resolution = <16>;
			status = "disabled";
		};

		pwm1_0_7: pwm@40580380 {
			compatible = "infineon,cat1-pwm";
			reg = <0x40580380 0x80>;
			system-interrupts = <442 6>;
			resolution = <16>;
			status = "disabled";
		};

		pwm1_0_8: pwm@40580400 {
			compatible = "infineon,cat1-pwm";
			reg = <0x40580400 0x80>;
			system-interrupts = <443 6>;
			resolution = <16>;
			status = "disabled";
		};

		pwm1_0_9: pwm@40580480 {
			compatible = "infineon,cat1-pwm";
			reg = <0x40580480 0x80>;
			system-interrupts = <444 6>;
			resolution = <16>;
			status = "disabled";
		};

		pwm1_0_10: pwm@40580500 {
			compatible = "infineon,cat1-pwm";
			reg = <0x40580500 0x80>;
			system-interrupts = <445 6>;
			resolution = <16>;
			status = "disabled";
		};

		pwm1_0_11: pwm@40580580 {
			compatible = "infineon,cat1-pwm";
			reg = <0x40580580 0x80>;
			system-interrupts = <446 6>;
			resolution = <16>;
			status = "disabled";
		};

		pwm1_0_12: pwm@40580600 {
			compatible = "infineon,cat1-pwm";
			reg = <0x40580600 0x80>;
			system-interrupts = <447 6>;
			resolution = <16>;
			status = "disabled";
		};

		pwm1_0_13: pwm@40580680 {
			compatible = "infineon,cat1-pwm";
			reg = <0x40580680 0x80>;
			system-interrupts = <448 6>;
			resolution = <16>;
			status = "disabled";
		};

		pwm1_0_14: pwm@40580700 {
			compatible = "infineon,cat1-pwm";
			reg = <0x40580700 0x80>;
			system-interrupts = <449 6>;
			resolution = <16>;
			status = "disabled";
		};

		pwm1_0_15: pwm@40580780 {
			compatible = "infineon,cat1-pwm";
			reg = <0x40580780 0x80>;
			system-interrupts = <450 6>;
			resolution = <16>;
			status = "disabled";
		};

		pwm1_0_16: pwm@40580800 {
			compatible = "infineon,cat1-pwm";
			reg = <0x40580800 0x80>;
			system-interrupts = <451 6>;
			resolution = <16>;
			status = "disabled";
		};

		pwm1_0_17: pwm@40580880 {
			compatible = "infineon,cat1-pwm";
			reg = <0x40580880 0x80>;
			system-interrupts = <452 6>;
			resolution = <16>;
			status = "disabled";
		};

		pwm1_0_18: pwm@40580900 {
			compatible = "infineon,cat1-pwm";
			reg = <0x40580900 0x80>;
			system-interrupts = <453 6>;
			resolution = <16>;
			status = "disabled";
		};

		pwm1_0_19: pwm@40580980 {
			compatible = "infineon,cat1-pwm";
			reg = <0x40580980 0x80>;
			system-interrupts = <454 6>;
			resolution = <16>;
			status = "disabled";
		};

		pwm1_0_20: pwm@40580a00 {
			compatible = "infineon,cat1-pwm";
			reg = <0x40580a00 0x80>;
			system-interrupts = <455 6>;
			resolution = <16>;
			status = "disabled";
		};

		pwm1_0_21: pwm@40580a80 {
			compatible = "infineon,cat1-pwm";
			reg = <0x40580a80 0x80>;
			system-interrupts = <456 6>;
			resolution = <16>;
			status = "disabled";
		};

		pwm1_0_22: pwm@40580b00 {
			compatible = "infineon,cat1-pwm";
			reg = <0x40580b00 0x80>;
			system-interrupts = <457 6>;
			resolution = <16>;
			status = "disabled";
		};

		pwm1_0_23: pwm@40580b80 {
			compatible = "infineon,cat1-pwm";
			reg = <0x40580b80 0x80>;
			system-interrupts = <458 6>;
			resolution = <16>;
			status = "disabled";
		};

		pwm1_0_24: pwm@40580c00 {
			compatible = "infineon,cat1-pwm";
			reg = <0x40580c00 0x80>;
			system-interrupts = <459 6>;
			resolution = <16>;
			status = "disabled";
		};

		pwm1_0_25: pwm@40580c80 {
			compatible = "infineon,cat1-pwm";
			reg = <0x40580c80 0x80>;
			system-interrupts = <460 6>;
			resolution = <16>;
			status = "disabled";
		};

		pwm1_0_26: pwm@40580d00 {
			compatible = "infineon,cat1-pwm";
			reg = <0x40580d00 0x80>;
			system-interrupts = <461 6>;
			resolution = <16>;
			status = "disabled";
		};

		pwm1_0_27: pwm@40580d80 {
			compatible = "infineon,cat1-pwm";
			reg = <0x40580d80 0x80>;
			system-interrupts = <462 6>;
			resolution = <16>;
			status = "disabled";
		};

		pwm1_0_28: pwm@40580e00 {
			compatible = "infineon,cat1-pwm";
			reg = <0x40580e00 0x80>;
			system-interrupts = <463 6>;
			resolution = <16>;
			status = "disabled";
		};

		pwm1_0_29: pwm@40580e80 {
			compatible = "infineon,cat1-pwm";
			reg = <0x40580e80 0x80>;
			system-interrupts = <464 6>;
			resolution = <16>;
			status = "disabled";
		};

		pwm1_0_30: pwm@40580f00 {
			compatible = "infineon,cat1-pwm";
			reg = <0x40580f00 0x80>;
			system-interrupts = <465 6>;
			resolution = <16>;
			status = "disabled";
		};

		pwm1_0_31: pwm@40580f80 {
			compatible = "infineon,cat1-pwm";
			reg = <0x40580f80 0x80>;
			system-interrupts = <466 6>;
			resolution = <16>;
			status = "disabled";
		};

		pwm1_0_32: pwm@40581000 {
			compatible = "infineon,cat1-pwm";
			reg = <0x40581000 0x80>;
			system-interrupts = <467 6>;
			resolution = <16>;
			status = "disabled";
		};

		pwm1_0_33: pwm@40581080 {
			compatible = "infineon,cat1-pwm";
			reg = <0x40581080 0x80>;
			system-interrupts = <468 6>;
			resolution = <16>;
			status = "disabled";
		};

		pwm1_0_34: pwm@40581100 {
			compatible = "infineon,cat1-pwm";
			reg = <0x40581100 0x80>;
			system-interrupts = <469 6>;
			resolution = <16>;
			status = "disabled";
		};

		pwm1_0_35: pwm@40581180 {
			compatible = "infineon,cat1-pwm";
			reg = <0x40581180 0x80>;
			system-interrupts = <470 6>;
			resolution = <16>;
			status = "disabled";
		};

		pwm1_0_36: pwm@40581200 {
			compatible = "infineon,cat1-pwm";
			reg = <0x40581200 0x80>;
			system-interrupts = <471 6>;
			resolution = <16>;
			status = "disabled";
		};

		pwm1_0_37: pwm@40581280 {
			compatible = "infineon,cat1-pwm";
			reg = <0x40581280 0x80>;
			system-interrupts = <472 6>;
			resolution = <16>;
			status = "disabled";
		};

		pwm1_0_38: pwm@40581300 {
			compatible = "infineon,cat1-pwm";
			reg = <0x40581300 0x80>;
			system-interrupts = <473 6>;
			resolution = <16>;
			status = "disabled";
		};

		pwm1_0_39: pwm@40581380 {
			compatible = "infineon,cat1-pwm";
			reg = <0x40581380 0x80>;
			system-interrupts = <474 6>;
			resolution = <16>;
			status = "disabled";
		};

		pwm1_0_40: pwm@40581400 {
			compatible = "infineon,cat1-pwm";
			reg = <0x40581400 0x80>;
			system-interrupts = <475 6>;
			resolution = <16>;
			status = "disabled";
		};

		pwm1_0_41: pwm@40581480 {
			compatible = "infineon,cat1-pwm";
			reg = <0x40581480 0x80>;
			system-interrupts = <476 6>;
			resolution = <16>;
			status = "disabled";
		};

		pwm1_0_42: pwm@40581500 {
			compatible = "infineon,cat1-pwm";
			reg = <0x40581500 0x80>;
			system-interrupts = <477 6>;
			resolution = <16>;
			status = "disabled";
		};

		pwm1_0_43: pwm@40581580 {
			compatible = "infineon,cat1-pwm";
			reg = <0x40581580 0x80>;
			system-interrupts = <478 6>;
			resolution = <16>;
			status = "disabled";
		};

		pwm1_0_44: pwm@40581600 {
			compatible = "infineon,cat1-pwm";
			reg = <0x40581600 0x80>;
			system-interrupts = <479 6>;
			resolution = <16>;
			status = "disabled";
		};

		pwm1_0_45: pwm@40581680 {
			compatible = "infineon,cat1-pwm";
			reg = <0x40581680 0x80>;
			system-interrupts = <480 6>;
			resolution = <16>;
			status = "disabled";
		};

		pwm1_0_46: pwm@40581700 {
			compatible = "infineon,cat1-pwm";
			reg = <0x40581700 0x80>;
			system-interrupts = <481 6>;
			resolution = <16>;
			status = "disabled";
		};

		pwm1_0_47: pwm@40581780 {
			compatible = "infineon,cat1-pwm";
			reg = <0x40581780 0x80>;
			system-interrupts = <482 6>;
			resolution = <16>;
			status = "disabled";
		};

		pwm1_0_48: pwm@40581800 {
			compatible = "infineon,cat1-pwm";
			reg = <0x40581800 0x80>;
			system-interrupts = <483 6>;
			resolution = <16>;
			status = "disabled";
		};

		pwm1_0_49: pwm@40581880 {
			compatible = "infineon,cat1-pwm";
			reg = <0x40581880 0x80>;
			system-interrupts = <484 6>;
			resolution = <16>;
			status = "disabled";
		};

		pwm1_0_50: pwm@40581900 {
			compatible = "infineon,cat1-pwm";
			reg = <0x40581900 0x80>;
			system-interrupts = <485 6>;
			resolution = <16>;
			status = "disabled";
		};

		pwm1_0_51: pwm@40581980 {
			compatible = "infineon,cat1-pwm";
			reg = <0x40581980 0x80>;
			system-interrupts = <486 6>;
			resolution = <16>;
			status = "disabled";
		};

		pwm1_0_52: pwm@40581a00 {
			compatible = "infineon,cat1-pwm";
			reg = <0x40581a00 0x80>;
			system-interrupts = <487 6>;
			resolution = <16>;
			status = "disabled";
		};

		pwm1_0_53: pwm@40581a80 {
			compatible = "infineon,cat1-pwm";
			reg = <0x40581a80 0x80>;
			system-interrupts = <488 6>;
			resolution = <16>;
			status = "disabled";
		};

		pwm1_0_54: pwm@40581b00 {
			compatible = "infineon,cat1-pwm";
			reg = <0x40581b00 0x80>;
			system-interrupts = <489 6>;
			resolution = <16>;
			status = "disabled";
		};

		pwm1_0_55: pwm@40581b80 {
			compatible = "infineon,cat1-pwm";
			reg = <0x40581b80 0x80>;
			system-interrupts = <490 6>;
			resolution = <16>;
			status = "disabled";
		};

		pwm1_0_56: pwm@40581c00 {
			compatible = "infineon,cat1-pwm";
			reg = <0x40581c00 0x80>;
			system-interrupts = <491 6>;
			resolution = <16>;
			status = "disabled";
		};

		pwm1_0_57: pwm@40581c80 {
			compatible = "infineon,cat1-pwm";
			reg = <0x40581c80 0x80>;
			system-interrupts = <492 6>;
			resolution = <16>;
			status = "disabled";
		};

		pwm1_0_58: pwm@40581d00 {
			compatible = "infineon,cat1-pwm";
			reg = <0x40581d00 0x80>;
			system-interrupts = <493 6>;
			resolution = <16>;
			status = "disabled";
		};

		pwm1_0_59: pwm@40581d80 {
			compatible = "infineon,cat1-pwm";
			reg = <0x40581d80 0x80>;
			system-interrupts = <494 6>;
			resolution = <16>;
			status = "disabled";
		};

		pwm1_0_60: pwm@40581e00 {
			compatible = "infineon,cat1-pwm";
			reg = <0x40581e00 0x80>;
			system-interrupts = <495 6>;
			resolution = <16>;
			status = "disabled";
		};

		pwm1_0_61: pwm@40581e80 {
			compatible = "infineon,cat1-pwm";
			reg = <0x40581e80 0x80>;
			system-interrupts = <496 6>;
			resolution = <16>;
			status = "disabled";
		};

		pwm1_0_62: pwm@40581f00 {
			compatible = "infineon,cat1-pwm";
			reg = <0x40581f00 0x80>;
			system-interrupts = <497 6>;
			resolution = <16>;
			status = "disabled";
		};

		pwm1_0_63: pwm@40581f80 {
			compatible = "infineon,cat1-pwm";
			reg = <0x40581f80 0x80>;
			system-interrupts = <498 6>;
			resolution = <16>;
			status = "disabled";
		};

		pwm1_0_64: pwm@40582000 {
			compatible = "infineon,cat1-pwm";
			reg = <0x40582000 0x80>;
			system-interrupts = <499 6>;
			resolution = <16>;
			status = "disabled";
		};

		pwm1_0_65: pwm@40582080 {
			compatible = "infineon,cat1-pwm";
			reg = <0x40582080 0x80>;
			system-interrupts = <500 6>;
			resolution = <16>;
			status = "disabled";
		};

		pwm1_0_66: pwm@40582100 {
			compatible = "infineon,cat1-pwm";
			reg = <0x40582100 0x80>;
			system-interrupts = <501 6>;
			resolution = <16>;
			status = "disabled";
		};

		pwm1_0_67: pwm@40582180 {
			compatible = "infineon,cat1-pwm";
			reg = <0x40582180 0x80>;
			system-interrupts = <502 6>;
			resolution = <16>;
			status = "disabled";
		};

		pwm1_0_68: pwm@40582200 {
			compatible = "infineon,cat1-pwm";
			reg = <0x40582200 0x80>;
			system-interrupts = <503 6>;
			resolution = <16>;
			status = "disabled";
		};

		pwm1_0_69: pwm@40582280 {
			compatible = "infineon,cat1-pwm";
			reg = <0x40582280 0x80>;
			system-interrupts = <504 6>;
			resolution = <16>;
			status = "disabled";
		};

		pwm1_0_70: pwm@40582300 {
			compatible = "infineon,cat1-pwm";
			reg = <0x40582300 0x80>;
			system-interrupts = <505 6>;
			resolution = <16>;
			status = "disabled";
		};

		pwm1_0_71: pwm@40582380 {
			compatible = "infineon,cat1-pwm";
			reg = <0x40582380 0x80>;
			system-interrupts = <506 6>;
			resolution = <16>;
			status = "disabled";
		};

		pwm1_0_72: pwm@40582400 {
			compatible = "infineon,cat1-pwm";
			reg = <0x40582400 0x80>;
			system-interrupts = <507 6>;
			resolution = <16>;
			status = "disabled";
		};

		pwm1_0_73: pwm@40582480 {
			compatible = "infineon,cat1-pwm";
			reg = <0x40582480 0x80>;
			system-interrupts = <508 6>;
			resolution = <16>;
			status = "disabled";
		};

		pwm1_0_74: pwm@40582500 {
			compatible = "infineon,cat1-pwm";
			reg = <0x40582500 0x80>;
			system-interrupts = <509 6>;
			resolution = <16>;
			status = "disabled";
		};

		pwm1_0_75: pwm@40582580 {
			compatible = "infineon,cat1-pwm";
			reg = <0x40582580 0x80>;
			system-interrupts = <510 6>;
			resolution = <16>;
			status = "disabled";
		};

		pwm1_0_76: pwm@40582600 {
			compatible = "infineon,cat1-pwm";
			reg = <0x40582600 0x80>;
			system-interrupts = <511 6>;
			resolution = <16>;
			status = "disabled";
		};

		pwm1_0_77: pwm@40582680 {
			compatible = "infineon,cat1-pwm";
			reg = <0x40582680 0x80>;
			system-interrupts = <512 6>;
			resolution = <16>;
			status = "disabled";
		};

		pwm1_0_78: pwm@40582700 {
			compatible = "infineon,cat1-pwm";
			reg = <0x40582700 0x80>;
			system-interrupts = <513 6>;
			resolution = <16>;
			status = "disabled";
		};

		pwm1_0_79: pwm@40582780 {
			compatible = "infineon,cat1-pwm";
			reg = <0x40582780 0x80>;
			system-interrupts = <514 6>;
			resolution = <16>;
			status = "disabled";
		};

		pwm1_0_80: pwm@40582800 {
			compatible = "infineon,cat1-pwm";
			reg = <0x40582800 0x80>;
			system-interrupts = <515 6>;
			resolution = <16>;
			status = "disabled";
		};

		pwm1_0_81: pwm@40582880 {
			compatible = "infineon,cat1-pwm";
			reg = <0x40582880 0x80>;
			system-interrupts = <516 6>;
			resolution = <16>;
			status = "disabled";
		};

		pwm1_0_82: pwm@40582900 {
			compatible = "infineon,cat1-pwm";
			reg = <0x40582900 0x80>;
			system-interrupts = <517 6>;
			resolution = <16>;
			status = "disabled";
		};

		pwm1_0_83: pwm@40582980 {
			compatible = "infineon,cat1-pwm";
			reg = <0x40582980 0x80>;
			system-interrupts = <518 6>;
			resolution = <16>;
			status = "disabled";
		};

		pwm1_1_0: pwm@40588000 {
			compatible = "infineon,cat1-pwm";
			reg = <0x40588000 0x80>;
			system-interrupts = <522 6>;
			resolution = <16>;
			status = "disabled";
		};

		pwm1_1_1: pwm@40588080 {
			compatible = "infineon,cat1-pwm";
			reg = <0x40588080 0x80>;
			system-interrupts = <523 6>;
			resolution = <16>;
			status = "disabled";
		};

		pwm1_1_2: pwm@40588100 {
			compatible = "infineon,cat1-pwm";
			reg = <0x40588100 0x80>;
			system-interrupts = <524 6>;
			resolution = <16>;
			status = "disabled";
		};

		pwm1_1_3: pwm@40588180 {
			compatible = "infineon,cat1-pwm";
			reg = <0x40588180 0x80>;
			system-interrupts = <525 6>;
			resolution = <16>;
			status = "disabled";
		};

		pwm1_1_4: pwm@40588200 {
			compatible = "infineon,cat1-pwm";
			reg = <0x40588200 0x80>;
			system-interrupts = <526 6>;
			resolution = <16>;
			status = "disabled";
		};

		pwm1_1_5: pwm@40588280 {
			compatible = "infineon,cat1-pwm";
			reg = <0x40588280 0x80>;
			system-interrupts = <527 6>;
			resolution = <16>;
			status = "disabled";
		};

		pwm1_1_6: pwm@40588300 {
			compatible = "infineon,cat1-pwm";
			reg = <0x40588300 0x80>;
			system-interrupts = <528 6>;
			resolution = <16>;
			status = "disabled";
		};

		pwm1_1_7: pwm@40588380 {
			compatible = "infineon,cat1-pwm";
			reg = <0x40588380 0x80>;
			system-interrupts = <529 6>;
			resolution = <16>;
			status = "disabled";
		};

		pwm1_1_8: pwm@40588400 {
			compatible = "infineon,cat1-pwm";
			reg = <0x40588400 0x80>;
			system-interrupts = <530 6>;
			resolution = <16>;
			status = "disabled";
		};

		pwm1_1_9: pwm@40588480 {
			compatible = "infineon,cat1-pwm";
			reg = <0x40588480 0x80>;
			system-interrupts = <531 6>;
			resolution = <16>;
			status = "disabled";
		};

		pwm1_1_10: pwm@40588500 {
			compatible = "infineon,cat1-pwm";
			reg = <0x40588500 0x80>;
			system-interrupts = <532 6>;
			resolution = <16>;
			status = "disabled";
		};

		pwm1_1_11: pwm@40588580 {
			compatible = "infineon,cat1-pwm";
			reg = <0x40588580 0x80>;
			system-interrupts = <533 6>;
			resolution = <16>;
			status = "disabled";
		};

		pwm1_2_0: pwm@40590000 {
			compatible = "infineon,cat1-pwm";
			reg = <0x40590000 0x80>;
			system-interrupts = <537 6>;
			resolution = <32>;
			status = "disabled";
		};

		pwm1_2_1: pwm@40590080 {
			compatible = "infineon,cat1-pwm";
			reg = <0x40590080 0x80>;
			system-interrupts = <538 6>;
			resolution = <32>;
			status = "disabled";
		};

		pwm1_2_2: pwm@40590100 {
			compatible = "infineon,cat1-pwm";
			reg = <0x40590100 0x80>;
			system-interrupts = <539 6>;
			resolution = <32>;
			status = "disabled";
		};

		pwm1_2_3: pwm@40590180 {
			compatible = "infineon,cat1-pwm";
			reg = <0x40590180 0x80>;
			system-interrupts = <540 6>;
			resolution = <32>;
			status = "disabled";
		};

		pwm1_2_4: pwm@40590200 {
			compatible = "infineon,cat1-pwm";
			reg = <0x40590200 0x80>;
			system-interrupts = <541 6>;
			resolution = <32>;
			status = "disabled";
		};

		pwm1_2_5: pwm@40590280 {
			compatible = "infineon,cat1-pwm";
			reg = <0x40590280 0x80>;
			system-interrupts = <542 6>;
			resolution = <32>;
			status = "disabled";
		};

		pwm1_2_6: pwm@40590300 {
			compatible = "infineon,cat1-pwm";
			reg = <0x40590300 0x80>;
			system-interrupts = <543 6>;
			resolution = <32>;
			status = "disabled";
		};

		pwm1_2_7: pwm@40590380 {
			compatible = "infineon,cat1-pwm";
			reg = <0x40590380 0x80>;
			system-interrupts = <544 6>;
			resolution = <32>;
			status = "disabled";
		};

		pwm1_2_8: pwm@40590400 {
			compatible = "infineon,cat1-pwm";
			reg = <0x40590400 0x80>;
			system-interrupts = <545 6>;
			resolution = <32>;
			status = "disabled";
		};

		pwm1_2_9: pwm@40590480 {
			compatible = "infineon,cat1-pwm";
			reg = <0x40590480 0x80>;
			system-interrupts = <546 6>;
			resolution = <32>;
			status = "disabled";
		};

		pwm1_2_10: pwm@40590500 {
			compatible = "infineon,cat1-pwm";
			reg = <0x40590500 0x80>;
			system-interrupts = <547 6>;
			resolution = <32>;
			status = "disabled";
		};

		pwm1_2_11: pwm@40590580 {
			compatible = "infineon,cat1-pwm";
			reg = <0x40590580 0x80>;
			system-interrupts = <548 6>;
			resolution = <32>;
			status = "disabled";
		};

		pwm1_2_12: pwm@40590600 {
			compatible = "infineon,cat1-pwm";
			reg = <0x40590600 0x80>;
			system-interrupts = <549 6>;
			resolution = <32>;
			status = "disabled";
		};

		dma0: dw@40280000 {
			#dma-cells = <1>;
			compatible = "infineon,cat1-dma";
			reg = <0x40280000 0x10000>;
			dma-channels = <143>;
			system-interrupts = <227 6>, /* CH0 */
					    <228 6>, /* CH1 */
					    <229 6>, /* CH2 */
					    <230 6>, /* CH3 */
					    <231 6>, /* CH4 */
					    <232 6>, /* CH5 */
					    <233 6>, /* CH6 */
					    <234 6>, /* CH7 */
					    <235 6>, /* CH8 */
					    <236 6>, /* CH9 */
					    <237 6>, /* CH10 */
					    <238 6>, /* CH11 */
					    <239 6>, /* CH12 */
					    <240 6>, /* CH13 */
					    <241 6>, /* CH14 */
					    <242 6>, /* CH15 */
					    <243 6>, /* CH16 */
					    <244 6>, /* CH17 */
					    <245 6>, /* CH18 */
					    <246 6>, /* CH19 */
					    <247 6>, /* CH20 */
					    <248 6>, /* CH21 */
					    <249 6>, /* CH22 */
					    <250 6>, /* CH23 */
					    <251 6>, /* CH24 */
					    <252 6>, /* CH25 */
					    <253 6>, /* CH26 */
					    <254 6>, /* CH27 */
					    <255 6>, /* CH28 */
					    <256 6>, /* CH29 */
					    <257 6>, /* CH30 */
					    <258 6>, /* CH31 */
					    <259 6>, /* CH32 */
					    <260 6>, /* CH33 */
					    <261 6>, /* CH34 */
					    <262 6>, /* CH35 */
					    <263 6>, /* CH36 */
					    <264 6>, /* CH37 */
					    <265 6>, /* CH38 */
					    <266 6>, /* CH39 */
					    <267 6>, /* CH40 */
					    <268 6>, /* CH41 */
					    <269 6>, /* CH42 */
					    <270 6>, /* CH43 */
					    <271 6>, /* CH44 */
					    <272 6>, /* CH45 */
					    <273 6>, /* CH46 */
					    <274 6>, /* CH47 */
					    <275 6>, /* CH48 */
					    <276 6>, /* CH49 */
					    <277 6>, /* CH50 */
					    <278 6>, /* CH51 */
					    <279 6>, /* CH52 */
					    <280 6>, /* CH53 */
					    <281 6>, /* CH54 */
					    <282 6>, /* CH55 */
					    <283 6>, /* CH56 */
					    <284 6>, /* CH57 */
					    <285 6>, /* CH58 */
					    <286 6>, /* CH59 */
					    <287 6>, /* CH60 */
					    <288 6>, /* CH61 */
					    <289 6>, /* CH62 */
					    <290 6>, /* CH63 */
					    <291 6>, /* CH64 */
					    <292 6>, /* CH65 */
					    <293 6>, /* CH66 */
					    <294 6>, /* CH67 */
					    <295 6>, /* CH68 */
					    <296 6>, /* CH69 */
					    <297 6>, /* CH70 */
					    <298 6>, /* CH71 */
					    <299 6>, /* CH72 */
					    <300 6>, /* CH73 */
					    <301 6>, /* CH74 */
					    <302 6>, /* CH75 */
					    <303 6>, /* CH76 */
					    <304 6>, /* CH77 */
					    <305 6>, /* CH78 */
					    <306 6>, /* CH79 */
					    <307 6>, /* CH80 */
					    <308 6>, /* CH81 */
					    <309 6>, /* CH82 */
					    <310 6>, /* CH83 */
					    <311 6>, /* CH84 */
					    <312 6>, /* CH85 */
					    <313 6>, /* CH86 */
					    <314 6>, /* CH87 */
					    <315 6>, /* CH88 */
					    <316 6>, /* CH89 */
					    <317 6>, /* CH90 */
					    <318 6>, /* CH91 */
					    <319 6>, /* CH92 */
					    <320 6>, /* CH93 */
					    <321 6>, /* CH94 */
					    <322 6>, /* CH95 */
					    <323 6>, /* CH96 */
					    <324 6>, /* CH97 */
					    <325 6>, /* CH98 */
					    <326 6>, /* CH99 */
					    <327 6>, /* CH100 */
					    <328 6>, /* CH101 */
					    <329 6>, /* CH102 */
					    <330 6>, /* CH103 */
					    <331 6>, /* CH104 */
					    <332 6>, /* CH105 */
					    <333 6>, /* CH106 */
					    <334 6>, /* CH107 */
					    <335 6>, /* CH108 */
					    <336 6>, /* CH109 */
					    <337 6>, /* CH110 */
					    <338 6>, /* CH111 */
					    <339 6>, /* CH112 */
					    <340 6>, /* CH113 */
					    <341 6>, /* CH114 */
					    <342 6>, /* CH115 */
					    <343 6>, /* CH116 */
					    <344 6>, /* CH117 */
					    <345 6>, /* CH118 */
					    <346 6>, /* CH119 */
					    <347 6>, /* CH120 */
					    <348 6>, /* CH121 */
					    <349 6>, /* CH122 */
					    <350 6>, /* CH123 */
					    <351 6>, /* CH124 */
					    <352 6>, /* CH125 */
					    <353 6>, /* CH126 */
					    <354 6>, /* CH127 */
					    <355 6>, /* CH128 */
					    <356 6>, /* CH129 */
					    <357 6>, /* CH130 */
					    <358 6>, /* CH131 */
					    <359 6>, /* CH132 */
					    <360 6>, /* CH133 */
					    <361 6>, /* CH134 */
					    <362 6>, /* CH135 */
					    <363 6>, /* CH136 */
					    <364 6>, /* CH137 */
					    <365 6>, /* CH138 */
					    <366 6>, /* CH139 */
					    <367 6>, /* CH140 */
					    <368 6>, /* CH141 */
					    <369 6>; /* CH142 */
			status = "disabled";
		};

		dma1: dw@40290000 {
			#dma-cells = <1>;
			compatible = "infineon,cat1-dma";
			reg = <0x40290000 0x10000>;
			dma-channels = <65>;
			system-interrupts = <370 6>, /* CH0 */
					    <371 6>, /* CH1 */
					    <372 6>, /* CH2 */
					    <373 6>, /* CH3 */
					    <374 6>, /* CH4 */
					    <375 6>, /* CH5 */
					    <376 6>, /* CH6 */
					    <377 6>, /* CH7 */
					    <378 6>, /* CH8 */
					    <379 6>, /* CH9 */
					    <380 6>, /* CH10 */
					    <381 6>, /* CH11 */
					    <382 6>, /* CH12 */
					    <383 6>, /* CH13 */
					    <384 6>, /* CH14 */
					    <385 6>, /* CH15 */
					    <386 6>, /* CH16 */
					    <387 6>, /* CH17 */
					    <388 6>, /* CH18 */
					    <389 6>, /* CH19 */
					    <390 6>, /* CH20 */
					    <391 6>, /* CH21 */
					    <392 6>, /* CH22 */
					    <393 6>, /* CH23 */
					    <394 6>, /* CH24 */
					    <395 6>, /* CH25 */
					    <396 6>, /* CH26 */
					    <397 6>, /* CH27 */
					    <398 6>, /* CH28 */
					    <399 6>, /* CH29 */
					    <400 6>, /* CH30 */
					    <401 6>, /* CH31 */
					    <402 6>, /* CH32 */
					    <403 6>, /* CH33 */
					    <404 6>, /* CH34 */
					    <405 6>, /* CH35 */
					    <406 6>, /* CH36 */
					    <407 6>, /* CH37 */
					    <408 6>, /* CH38 */
					    <409 6>, /* CH39 */
					    <410 6>, /* CH40 */
					    <411 6>, /* CH41 */
					    <412 6>, /* CH42 */
					    <413 6>, /* CH43 */
					    <414 6>, /* CH44 */
					    <415 6>, /* CH45 */
					    <416 6>, /* CH46 */
					    <417 6>, /* CH47 */
					    <418 6>, /* CH48 */
					    <419 6>, /* CH49 */
					    <420 6>, /* CH50 */
					    <421 6>, /* CH51 */
					    <422 6>, /* CH52 */
					    <423 6>, /* CH53 */
					    <424 6>, /* CH54 */
					    <425 6>, /* CH55 */
					    <426 6>, /* CH56 */
					    <427 6>, /* CH57 */
					    <428 6>, /* CH58 */
					    <429 6>, /* CH59 */
					    <430 6>, /* CH60 */
					    <431 6>, /* CH61 */
					    <432 6>, /* CH62 */
					    <433 6>, /* CH63 */
					    <434 6>; /* CH64 */
			status = "disabled";
		};

		sdhc0: sdhc@40460000 {
			compatible = "infineon,cat1-sdhc-sdio";
			reg = <0x40460000 0x2000>;
			system-interrupts = <563 6>, /* SDIO wakeup interrupt for mxsdhc */
					    <562 6>; /* Consolidated interrupt for mxsdhc */
			status = "disabled";
		};
	};
};
